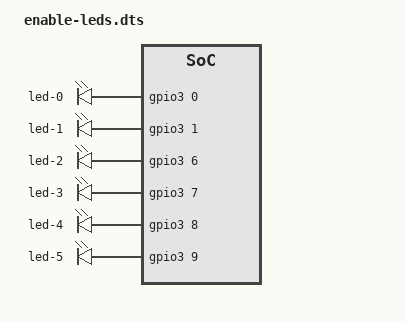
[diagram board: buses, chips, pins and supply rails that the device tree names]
/dts-v1/;
/plugin/;

&{/} {
	leds {
		compatible = "gpio-leds";

		pinctrl-names = "default";
		pinctrl-0 = <&pinctrl_leds_yavia>;

		/* SODIMM 52 - LD1_RED */
		led-0 {
			gpios = <&gpio3 0 0>;
			default-state = "off";
		};
		/* SODIMM 54 - LD1_GREEN */
		led-1 {
			gpios = <&gpio3 1 0>;
			default-state = "off";
		};
		/* SODIMM 56 - LD1_BLUE */
		led-2 {
			gpios = <&gpio3 6 0>;
			default-state = "off";
		};
		/* SODIMM 58 - LD2_RED */
		led-3 {
			gpios = <&gpio3 7 0>;
			default-state = "off";
		};
		/* SODIMM 60 - LD2_GREEN */
		led-4 {
			gpios = <&gpio3 8 0>;
			default-state = "off";
		};
		/* SODIMM 62 - LD2_BLUE */
		led-5 {
			gpios = <&gpio3 9 0>;
			default-state = "off";
		};
	};
};

&flexspi {
	status = "disabled";
};

&iomuxc {
	pinctrl_leds_yavia: ledsyaviagrp {
		fsl,pins = <
			0x0E0 0x340 0x000 0x5 0x0 0x106	/* SODIMM 52 */
			0x0E4 0x344 0x000 0x5 0x0 0x106	/* SODIMM 54 */
			0x0F8 0x358 0x000 0x5 0x0 0x106	/* SODIMM 56 */
			0x0FC 0x35C 0x000 0x5 0x0 0x106	/* SODIMM 58 */
			0x100 0x360 0x000 0x5 0x0 0x106	/* SODIMM 60 */
			0x104 0x364 0x000 0x5 0x0 0x106	/* SODIMM 62 */
		>;
	};
};
